# D1H.pdf register map
Vendor: Allwinner; Series: D1H.pdf; File version: 0.1
CPU: XuanTie C906 RISC-V CPU 0, little endian, MPU, FPU, double-precision FPU, 0 interrupt priority bits
Registers are 32-bit, read-write, reset 0x0 unless marked. A register's access mark holds for its fields unless they carry their own. Offsets are from the block's base; [hi:lo] are bit positions; lines under a group give offsets from that group; {n}, {i} and the like mark numbered series; 'fields as' and 'values as' point back to an identical list.

## Audio_Codec (part 1 of 5)
Base 0x02030000
0x00 ANALOG DOMAIN REGISTER group
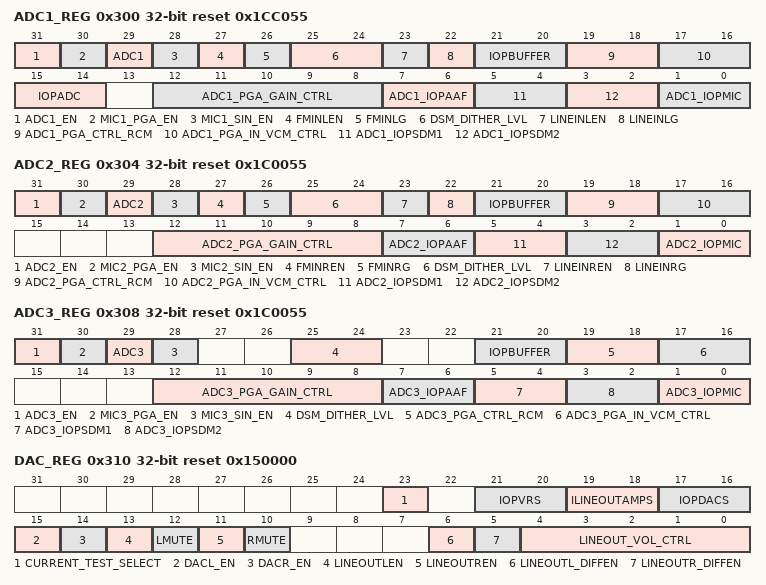
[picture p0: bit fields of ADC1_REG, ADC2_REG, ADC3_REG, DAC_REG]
  0x300 ADC1_REG reset 0x1CC055 — ADC1 Analog Control Register
    [31] ADC1_EN — ADC1 Channel Enable 0: Disabled 1: Enabled
      0=Disabled; 1=Enabled
    [30] MIC1_PGA_EN — MIC1 PGA Enable 0: Disabled 1: Enabled
      0=Disabled; 1=Enabled
    [29] ADC1 — Dither Control 0: New Dither Off 1: New Dither On
      0=New_Dither_Off; 1=New_Dither_On
    [28] MIC1_SIN_EN — MIC1 Single Input Enable 0: Disable 1: Enable
      0=Disable; 1=Enable
    [27] FMINLEN — FMINL Enable 0: Disable 1: Enable
      0=Disable; 1=Enable
    [26] FMINLG — FMINL Gain Control 0: 0 dB 1: 6 dB
      0=_0_dB; 1=_6_dB
    [25:24] DSM_DITHER_LVL — Dither Level Control (Dither level is positive ralated to the ctrl bits) 00: No Level 01: Min Level 10: Middle Level 11: Max Level
      0=No_Level; 1=Min_Level; 2=Middle_Level; 3=Max_Level
    [23] LINEINLEN — LINEINL Enable 0: Disable 1: Enable
      0=Disable; 1=Enable
    [22] LINEINLG — LINEINL Gain Control 0: 0 dB 1: 6 dB
      0=_0_dB; 1=_6_dB
    [21:20] IOPBUFFER — PGA Vcm Buffer OP Bias Current Select 00: 6 uA 01: 7 uA 10: 8 uA 11: 9 uA
      {v}=_{v+6}_uA (v=0..3)
    [19:18] ADC1_PGA_CTRL_RCM — ADC1 PGA Common Mode Input Impedance Control for MICIN 00: 100 kΩ 01: 75 kΩ 10: 50 kΩ 11: 25 kΩ
      0=_100_kΩ; 1=_75_kΩ; 2=_50_kΩ; 3=_25_kΩ
    [17:16] ADC1_PGA_IN_VCM_CTRL — ADC1 PGA Common-Mode Voltage Control 00: 900 mV 01: 800 mV 10: 750 mV 11: 700 mV
      0=_900_mV; 1=_800_mV; 2=_750_mV; 3=_700_mV
    [15:14] IOPADC — ADC1-ADC3 Bias Current Select 00: 1 uA 01: 2 uA 10: 3 uA 11: 4 uA
      {v}=_{v+1}_uA (v=0..3)
    [12:8] ADC1_PGA_GAIN_CTRL — ADC1 PGA gain settings: 0x0: 0 dB 0x10: 21 dB 0x1: 6 dB 0x11: 22 dB 0x2: 6 dB 0x12: 23 dB 0x3: 6 dB 0x13: 24 dB 0x4: 9 dB 0x14: 25 dB 0x5: 10 dB 0x15: 26 dB 0x6: 11 dB 0x16: 27 dB 0x7: 12 dB 0x17: 28 dB 0x8: 13 dB 0x18: 29 dB 0x9: 14 dB 0x19: 30 dB 0xA: 15 dB 0x1A: 31 dB 0xB: 16 dB 0x1B: 32 dB 0xC: 17 dB 0x1C: 33 dB 0xD: 18 dB 0x1D: 34 dB 0xE: 19 dB 0x1E: 35 dB 0xF: 20 dB 0x1F: 36 dB
    [7:6] ADC1_IOPAAF — ADC1 OP AAF Bias Current Select 00: 1.50*IOPADC 01: 1.75*IOPADC 10: 2.00*IOPADC 11: 2.25*IOPADC IOPADC is defined by ADC1_REG<15:14> from 1 uA to 4 uA. For example: ADC1_REG<15:14> = 11, IOPADC = 4 uA 00: 1.50*4 uA = 6 uA 01: 1.75*4 uA = 7 uA 10: 2.00*4 uA = 8 uA 11: 2.25*4 uA = 9 uA
      0=_1_point_50_times_IOPADC (1.50*IOPADC); 1=_1_point_75_times_IOPADC (1.75*IOPADC); 2=_2_point_00_times_IOPADC (2.00*IOPADC); 3=_2_point_25_times_IOPADC (2.25*IOPADC IOPADC is defined by ADC1_REG<15:14> from 1 uA to 4 uA. For example: ADC1_REG<15:14> = 11, IOPADC = 4 uA); 0=_1_point_50_times_4_uA (1.50*4 uA = 6 uA); 1=_1_point_75_times_4_uA (1.75*4 uA = 7 uA); 2=_2_point_00_times_4_uA (2.00*4 uA = 8 uA); 3=_2_point_25_times_4_uA (2.25*4 uA = 9 uA)
    [5:4] ADC1_IOPSDM1 — ADC1 OP SDM Bias Current Select 1 00: 1.50*IOPADC 01: 1.75*IOPADC 10: 2.00*IOPADC 11: 2.25*IOPADC IOPADC is defined by ADC1_REG<15:14> from 1 uA to 4 uA.
      0=_1_point_50_times_IOPADC (1.50*IOPADC); 1=_1_point_75_times_IOPADC (1.75*IOPADC); 2=_2_point_00_times_IOPADC (2.00*IOPADC); 3=_2_point_25_times_IOPADC (2.25*IOPADC IOPADC is defined by ADC1_REG<15:14> from 1 uA to 4 uA.)
    [3:2] ADC1_IOPSDM2 — ADC1 OP SDM Bias Current Select 2 00: 1.50*IOPADC 01: 1.75*IOPADC 10: 2.00*IOPADC 11: 2.25*IOPADC IOPADC is defined by ADC1_REG<15:14> from 1 uA to 4 uA.
      values as ADC1_IOPSDM1
    [1:0] ADC1_IOPMIC — ADC1 OP MIC Bias Current Select 00: 1.50*IOPADC 01: 1.75*IOPADC 10: 2.00*IOPADC 11: 2.25*IOPADC IOPADC is defined by ADC1_REG<15:14> from 1 uA to 4 uA.
      values as ADC1_IOPSDM1
  0x304 ADC2_REG reset 0x1C0055 — ADC2 Analog Control Register
    [31] ADC2_EN — ADC2 Channel Enable 0: Disabled 1: Enabled
      0=Disabled; 1=Enabled
    [30] MIC2_PGA_EN — MIC2 PGA Enable 0: Disabled 1: Enabled
      0=Disabled; 1=Enabled
    [29] ADC2 — Dither Control 0: New Dither Off 1: New Dither On
      0=New_Dither_Off; 1=New_Dither_On
    [28] MIC2_SIN_EN — MIC2 Single Input Enable 0: Disable 1: Enable
      0=Disable; 1=Enable
    [27] FMINREN — FMINR Enable 0: Disable 1: Enable
      0=Disable; 1=Enable
    [26] FMINRG — FMINR Gain Control 0: 0 dB 1: 6 dB
      0=_0_dB; 1=_6_dB
    [25:24] DSM_DITHER_LVL — Dither Level Control (Dither level is positive ralated to the ctrl bits) 00: No Level 01: Min Level 10: Middle Level 11: Max Level
      0=No_Level; 1=Min_Level; 2=Middle_Level; 3=Max_Level
    [23] LINEINREN — LINEINR Enable 0: Disable 1: Enable
      0=Disable; 1=Enable
    [22] LINEINRG — LINEINR Gain Control 0: 0 dB 1: 6 dB
      0=_0_dB; 1=_6_dB
    [21:20] IOPBUFFER — PGA Vcm Buffer OP Bias Current Select 00: 6 uA 01: 7 uA 10: 8 uA 11: 9 uA
      {v}=_{v+6}_uA (v=0..3)
    [19:18] ADC2_PGA_CTRL_RCM — ADC2 PGA Common Mode Input Impedance Control for MICIN 00: 100 kΩ 01: 75 kΩ 10: 50 kΩ 11: 25 kΩ
      0=_100_kΩ; 1=_75_kΩ; 2=_50_kΩ; 3=_25_kΩ
    [17:16] ADC2_PGA_IN_VCM_CTRL — ADC2 PGA Common-Mode Voltage Control 00: 900 mV 01: 800 mV 10: 750 mV 11: 700 mV
      0=_900_mV; 1=_800_mV; 2=_750_mV; 3=_700_mV
    [12:8] ADC2_PGA_GAIN_CTRL — ADC2 PGA Gain Settings 0x0: 0 dB 0x10: 21 dB 0x1: 6 dB 0x11: 22 dB 0x2: 6 dB 0x12: 23 dB 0x3: 6 dB 0x13: 24 dB 0x4: 9 dB 0x14: 25 dB 0x5: 10 dB 0x15: 26 dB 0x6: 11 dB 0x16: 27 dB 0x7: 12 dB 0x17: 28 dB 0x8: 13 dB 0x18: 29 dB 0x9: 14 dB 0x19: 30 dB 0xA: 15 dB 0x1A: 31 dB 0xB: 16 dB 0x1B: 32 dB 0xC: 17 dB 0x1C: 33 dB 0xD: 18 dB 0x1D: 34 dB 0xE: 19 dB 0x1E: 35 dB 0xF: 20 dB 0x1F: 36 dB
    [7:6] ADC2_IOPAAF — ADC2 OP AAF Bias Current Select 00: 1.50*IOPADC 01: 1.75*IOPADC 10: 2.00*IOPADC 11: 2.25*IOPADC IOPADC is defined by ADC1_REG<15:14> from 1 uA to 4 uA.
      values as ANALOG.ADC1_REG.ADC1_IOPSDM1
    [5:4] ADC2_IOPSDM1 — ADC2 OP SDM Bias Current Select 1 00: 1.50*IOPADC 01: 1.75*IOPADC 10: 2.00*IOPADC 11: 2.25*IOPADC IOPADC is defined by ADC1_REG<15:14> from 1 uA to 4 uA.
      values as ANALOG.ADC1_REG.ADC1_IOPSDM1
    [3:2] ADC2_IOPSDM2 — ADC2 OP SDM Bias Current Select 2 00: 1.50*IOPADC 01: 1.75*IOPADC 10: 2.00*IOPADC 11: 2.25*IOPADC IOPADC is defined by ADC1_REG<15:14> from 1 uA to 4 uA.
      values as ANALOG.ADC1_REG.ADC1_IOPSDM1
    [1:0] ADC2_IOPMIC — ADC2 OP MIC Bias Current Select 00: 1.50*IOPADC 01: 1.75*IOPADC 10: 2.00*IOPADC 11: 2.25*IOPADC IOPADC is defined by ADC1_REG<15:14> from 1 uA to 4 uA.
      values as ANALOG.ADC1_REG.ADC1_IOPSDM1
  0x308 ADC3_REG reset 0x1C0055 — ADC3 Analog Control Register
    [31] ADC3_EN — ADC3 Channel Enable 0: Disabled 1: Enabled
      0=Disabled; 1=Enabled
    [30] MIC3_PGA_EN — MIC3 PGA Enable 0: Disabled 1: Enabled
      0=Disabled; 1=Enabled
    [29] ADC3 — Dither Control 0: New Dither Off 1: New Dither On
      0=New_Dither_Off; 1=New_Dither_On
    [28] MIC3_SIN_EN — MIC3 Single Input Enable 0: Disabled 1: Enabled
      0=Disabled; 1=Enabled
    [25:24] DSM_DITHER_LVL — Dither Level Control (Dither level is positive ralated to the ctrl bits) 00: No Level 01: Min Level 10: Middle Level 11: Max Level
      0=No_Level; 1=Min_Level; 2=Middle_Level; 3=Max_Level
    [21:20] IOPBUFFER — PGA Vcm Buffer OP Bias Current Select 00: 6 uA 01: 7 uA 10: 8 uA 11: 9 uA
      {v}=_{v+6}_uA (v=0..3)
    [19:18] ADC3_PGA_CTRL_RCM — ADC3 PGA Common Mode Input Impedance Control for MICIN 00: 100 kΩ 01: 75 kΩ 10: 50 kΩ 11: 25 kΩ
      0=_100_kΩ; 1=_75_kΩ; 2=_50_kΩ; 3=_25_kΩ
    [17:16] ADC3_PGA_IN_VCM_CTRL — ADC3 PGA Common-Mode Voltage Control 00: 900 mV 01: 800 mV 10: 750 mV 11: 700 mV
      0=_900_mV; 1=_800_mV; 2=_750_mV; 3=_700_mV
    [12:8] ADC3_PGA_GAIN_CTRL — ADC3 PGA Gain Settings 0x0: 0 dB 0x10: 21 dB 0x1: 6 dB 0x11: 22 dB 0x2: 6 dB 0x12: 23 dB 0x3: 6 dB 0x13: 24 dB 0x4: 9 dB 0x14: 25 dB 0x5: 10 dB 0x15: 26 dB 0x6: 11 dB 0x16: 27 dB 0x7: 12 dB 0x17: 28 dB 0x8: 13 dB 0x18: 29 dB 0x9: 14 dB 0x19: 30 dB 0xA: 15 dB 0x1A: 31 dB 0xB: 16 dB 0x1B: 32 dB 0xC: 17 dB 0x1C: 33 dB 0xD: 18 dB 0x1D: 34 dB 0xE: 19 dB 0x1E: 35 dB 0xF: 20 dB 0x1F: 36 dB
    [7:6] ADC3_IOPAAF — ADC3 OP AAF Bias Current Select 00: 1.50*IOPADC 01: 1.75*IOPADC 10: 2.00*IOPADC 11: 2.25*IOPADC IOPADC is defined by ADC1_REG<15:14> from 1 uA to 4 uA
      0=_1_point_50_times_IOPADC (1.50*IOPADC); 1=_1_point_75_times_IOPADC (1.75*IOPADC); 2=_2_point_00_times_IOPADC (2.00*IOPADC); 3=_2_point_25_times_IOPADC (2.25*IOPADC IOPADC is defined by ADC1_REG<15:14> from 1 uA to 4 uA)
    [5:4] ADC3_IOPSDM1 — ADC3 OP SDM Bias Current Select 1 00: 1.50*IOPADC 01: 1.75*IOPADC 10: 2.00*IOPADC 11: 2.25*IOPADC IOPADC is defined by ADC1_REG<15:14> from 1 uA to 4 uA
      values as ADC3_IOPAAF
    [3:2] ADC3_IOPSDM2 — ADC3 OP SDM Bias Current Select 2 00: 1.50*IOPADC 01: 1.75*IOPADC 10: 2.00*IOPADC 11: 2.25*IOPADC IOPADC is defined by ADC1_REG<15:14> from 1 uA to 4 uA
      values as ADC3_IOPAAF
    [1:0] ADC3_IOPMIC — ADC3 OP MIC Bias Current Select 00: 1.50*IOPADC 01: 1.75*IOPADC 10: 2.00*IOPADC 11: 2.25*IOPADC IOPADC is defined by ADC1_REG<15:14> from 1 uA to 4 uA
      values as ADC3_IOPAAF
  0x310 DAC_REG reset 0x150000 — DAC Analog Control Register
    [23] CURRENT_TEST_SELECT — Internal Current Sink Test Enable (from MICIN3P pin) 0: Normal 1: For Debug
      0=Normal; 1=For (For Debug)
    [21:20] IOPVRS — VRA2 Buffer OP and Headphone Feedback Buffer OP Bias Current Select 00: 6 uA 01: 7 uA 10: 8 uA 11: 9 uA
      {v}=_{v+6}_uA (v=0..3)
    [19:18] ILINEOUTAMPS — LINEOUTLL/R AMP Bias Current Select 00: 6 uA 01: 7 uA 10: 8 uA 11: 9 uA
      {v}=_{v+6}_uA (v=0..3)
    [17:16] IOPDACS — OPDACL/R Bias Current Select 00: 6 uA 01: 7 uA 10: 8 uA 11: 9 uA
      {v}=_{v+6}_uA (v=0..3)
    [15] DACL_EN — DACL Enable 0: Disabled 1: Enabled
      0=Disabled; 1=Enabled
    [14] DACR_EN — DACR Enable 0: Disabled 1: Enabled
      0=Disabled; 1=Enabled
    [13] LINEOUTLEN — Left Channel LINEOUT Enable 0: Disable 1: Enable
      0=Disable; 1=Enable
    [12] LMUTE — DACL to Left Channel LINEOUT Mute Control 0: Mute 1: Not mute
      0=Mute; 1=Not_mute
    [11] LINEOUTREN — Right Channel LINEOUT Enable 0: Disable 1: Enable
      0=Disable; 1=Enable
    [10] RMUTE — DACR to Right Channel LINEOUT Mute Control 0: Mute 1: Not mute
      0=Mute; 1=Not_mute
    [6] LINEOUTL_DIFFEN — Left Channel LINEOUT Output Control 0: Single-End 1: Differential
      0=single_End; 1=Differential
    [5] LINEOUTR_DIFFEN — Right Channel LINEOUT Output Control 0: Single-End 1: Differential
      0=single_End; 1=Differential
    [4:0] LINEOUT_VOL_CTRL — LINEOUT Volume Control. Total 30 level from 0x1F to 0x02 with the volume 0 dB to -43.5 dB, -1.5 dB/step, mute when 00000 & 00001.
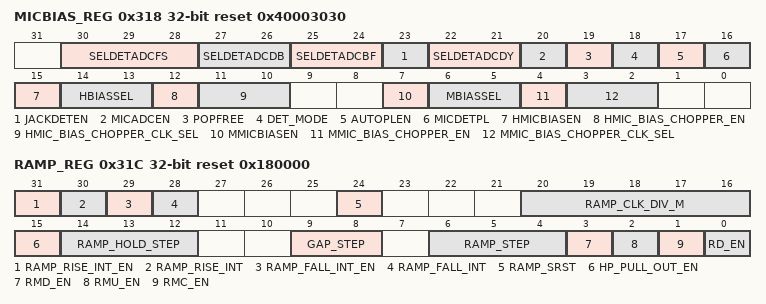
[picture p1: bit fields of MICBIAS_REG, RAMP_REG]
  0x318 MICBIAS_REG reset 0x40003030 — MICBIAS Analog Control Register
    [30:28] SELDETADCFS — Select sample interval of the ADC sample 000: 2 ms … 100: 32 ms … 111: 256 ms
      0=_2_ms; 4=_32_ms; 7=_256_ms
    [27:26] SELDETADCDB — Select debounce time when jack removal 00: 128 ms 01: 256 ms 10: 512 ms 11: 1024 ms
      0=_128_ms; 1=_256_ms; 2=_512_ms; 3=_1024_ms
    [25:24] SELDETADCBF — Select the time to enable HBIAS before MICADC work 00: 2 ms 01: 4 ms 10: 8 ms 11: 16 ms
      0=_2_ms; 1=_4_ms; 2=_8_ms; 3=_16_ms
    [23] JACKDETEN — Jack detect enable 0: Disable 1: Enable
      0=Disable; 1=Enable
    [22:21] SELDETADCDY — Select the delay time to pull low the micdet when jack removal 00: 0.5 ms 01: 1 ms 10: 1.5 ms 11: 2 ms
      0=_0_point_5_ms (0.5 ms); 1=_1_ms; 2=_1_point_5_ms (1.5 ms); 3=_2_ms
    [20] MICADCEN — Microphone detect ADC enable 0: Disabled 1: Enabled
      0=Disabled; 1=Enabled
    [19] POPFREE — When this bit is 0, HBIAS MICADC is controlled by registor
    [18] DET_MODE — MIC Detect Mode 0: Jack in pull low 1: Jack in pull high
      0=Jack_in_pull_low; 1=Jack_in_pull_high
    [17] AUTOPLEN — Enable the function to auto pull low MICDET when jack removal 0: Disabled 1: Enabled
      0=Disabled; 1=Enabled
    [16] MICDETPL — When this bit is 1and AUTOPLEN is 0, the MICDET is pulled down to GND.
    [15] HMICBIASEN — Headphone Microphone Bias Enable 0: Disabled 1: Enabled
      0=Disabled; 1=Enabled
    [14:13] HBIASSEL — HMICBIAS Voltage Level Select 00: 1.88 V 01: 2.09 V 10: 2.33 V 11: 2.55 V
      0=_1_point_88_V (1.88 V); 1=_2_point_09_V (2.09 V); 2=_2_point_33_V (2.33 V); 3=_2_point_55_V (2.55 V)
    [12] HMIC_BIAS_CHOPPER_EN — HMIC BIAS Chopper Enable 0: Disabled 1: Enabled
      0=Disabled; 1=Enabled
    [11:10] HMIC_BIAS_CHOPPER_CLK_SEL — HMIC BIAS Chopper Clock Select 00: 250 kHz 01: 500 kHz 10: 1 MHz 11: 2 MHz
      0=_250_kHz; 1=_500_kHz; 2=1 MHz; 3=2 MHz
    [7] MMICBIASEN — Master Microphone Bias Enable 0: Disabled 1: Enabled
      0=Disabled; 1=Enabled
    [6:5] MBIASSEL — MMICBIAS Voltage Level Select 00: 1.88 V 01: 2.09 V 10: 2.33 V 11: 2.50 V
      0=_1_point_88_V (1.88 V); 1=_2_point_09_V (2.09 V); 2=_2_point_33_V (2.33 V); 3=_2_point_50_V (2.50 V)
    [4] MMIC_BIAS_CHOPPER_EN — MMIC BIAS Chopper Enable 0: Disabled 1: Enabled
      0=Disabled; 1=Enabled
    [3:2] MMIC_BIAS_CHOPPER_CLK_SEL — MMIC BIAS Chopper Clock Select 00: 250 kHz 01: 500 kHz 10: 1 MHz 11: 2 MHz
      0=_250_kHz; 1=_500_kHz; 2=1 MHz; 3=2 MHz
  0x31C RAMP_REG reset 0x180000 — BIAS Analog Control Register
    [31] RAMP_RISE_INT_EN — RAMP Rise Interrupt Enable 0: Enabled 1: Disabled
      0=Enabled; 1=Disabled
    [30] RAMP_RISE_INT write-1-clears — RK Increase Upward Finish and Rampen Pull Down Instruction 0: No Pending IRQ 1: Ramp Rise Finish Pending Interrupt Write ‘1’ to clear this interrupt.
      0=No Pending IRQ; 1=Ramp Rise Finish Pending Interrupt Write ‘1’ to clear this interrupt
    [29] RAMP_FALL_INT_EN — RAMP Fall Int Enable 0: Enabled 1: Disabled
      0=Enabled; 1=Disabled
    [28] RAMP_FALL_INT write-1-clears — RK Downward Decrease Finish and Rampen Pull Down Instruction 0: No Pending IRQ 1: Ramp Fall Finish Pending Interrupt Write ‘1’ to clear this interrupt.
      0=No Pending IRQ; 1=Ramp Fall Finish Pending Interrupt Write ‘1’ to clear this interrupt
    [24] RAMP_SRST — Ramp Soft Reset 0: Disabled 1: Enabled
      0=Disabled; 1=Enabled
    [20:16] RAMP_CLK_DIV_M — Analog Ramp Clk Div Freq Value : M (from 0 to 31, Default: 24). Ana_Ramp_Clk= 24MHz/(M+1) Default Ramp Clk Freq: 24MHz/(24+1)=960 kHz
    [15] HP_PULL_OUT_EN — Heanphone Pullout Enable 0: Disabled 1: Enabled
      0=Disabled; 1=Enabled
    [14:12] RAMP_HOLD_STEP — RAMP HOLD STEP 000: 9600 001: 19200 010: 38400 011: 76800 100: 96000 101: 115200 110: 153600 111: 192000 Ramp Hold Time = Ramp Hold Step/Ramp Clk Freq When Ramp Clk Freq is equal to 960 kHz, the corresponding Ramp Hold time of each gear is: 000: 9600/960 kHz=10 ms 001: 19200/960 kHz=20 ms 010: 38400/960 kHz=40 ms 011: 76800/960 kHz=80 ms 100: 96000/960 kHz=100 ms 101: 115200/960 kHz=120 ms 110: 153600/960 kHz=160 ms 111: 192000/960 kHz=200 ms
      0=_9600; 1=_19200; 2=_38400; 3=_76800; 4=_96000; 5=_115200; 6=_153600; 7=192000 Ramp Hold Time = Ramp Hold Step/Ramp Clk Freq When Ramp Clk Freq is equal to 960 kHz, the corresponding Ramp Hold time of each gear is:; 0=_9600_slash_960_kHz_equals_10 (9600/960 kHz=10 ms); 1=_19200_slash_960_kHz_equals_20 (19200/960 kHz=20 ms); 2=_38400_slash_960_kHz_equals_40 (38400/960 kHz=40 ms); 3=_76800_slash_960_kHz_equals_80 (76800/960 kHz=80 ms); 4=_96000_slash_960_kHz_equals_100 (96000/960 kHz=100 ms); 5=_115200_slash_960_kHz_equals_120 (115200/960 kHz=120 ms); 6=_153600_slash_960_kHz_equals_160 (153600/960 kHz=160 ms); 7=_192000_slash_960_kHz_equals_200 (192000/960 kHz=200 ms)
    [9:8] GAP_STEP — Gap Step 00: ramp step 01: ramp step*2 10: ramp step*3 11: ramp step*4
      0=ramp_step; 1=ramp_step_times_2 (ramp step*2); 2=ramp_step_times_3 (ramp step*3); 3=ramp_step_times_4 (ramp step*4)
    [6:4] RAMP_STEP — RK Frequency Gear, Control Ramp Rise/Fall Total Time 000: 20 001: 30 010: 40 011: 60 100: 80 101: 120 110: 160 111: 240 Ramp Rise/Fall Total Time =(Ramp Step/Ramp Clk Freq)*4096 When Default Ramp Clk Freq is equal to 960 kHz, the corresponding time of each gear is: 000: (20/960kHz)*4096=85.3 ms 001: (30/960kHz)*4096=128 ms 010: (40/960kHz)*4096=170.6 ms 011: (60/960kHz)*4096=256 ms 100: (80/960kHz)*4096=341.3 ms 101: (120/960kHz)*4096=512 ms 110: (160/960kHz)*4096=682.6 ms 111: (240/960kHz)*4096=1024 ms
      0=_20; 1=_30; 2=_40; 3=_60; 4=_80; 5=_120; 6=_160; 7=240 Ramp Rise/Fall Total Time =(Ramp Step/Ramp Clk Freq)*4096 When Default Ramp Clk Freq is equal to 960 kHz, the corresponding time of each gear is:; 0=_openingparen_20_slash_960kHz_closingparen__times_4096_equals_85_point_3_ms ((20/960kHz)*4096=85.3 ms); 1=_openingparen_30_slash_960kHz_closingparen__times_4096_equals_128_ms ((30/960kHz)*4096=128 ms); 2=_openingparen_40_slash_960kHz_closingparen__times_4096_equals_170_point_6_ms ((40/960kHz)*4096=170.6 ms); 3=_openingparen_60_slash_960kHz_closingparen__times_4096_equals_256_ms ((60/960kHz)*4096=256 ms); 4=_openingparen_80_slash_960kHz_closingparen__times_4096_equals_341_point_3_ms ((80/960kHz)*4096=341.3 ms); 5=_openingparen_120_slash_960kHz_closingparen__times_4096_equals_512_ms ((120/960kHz)*4096=512 ms); 6=_openingparen_160_slash_960kHz_closingparen__times_4096_equals_682_point_6_ms ((160/960kHz)*4096=682.6 ms); 7=_openingparen_240_slash_960kHz_closingparen__times_4096_equals_1024_ms ((240/960kHz)*4096=1024 ms)
    [3] RMD_EN — Ramp Manual Down Enable 0: Disabled 1: Enabled
      0=Disabled; 1=Enabled
    [2] RMU_EN — Ramp Manual Up Enable 0: Disabled 1: Enabled
      0=Disabled; 1=Enabled
    [1] RMC_EN — Ramp Manual Control Enable 0: Disabled 1: Enabled
      0=Disabled; 1=Enabled
    [0] RD_EN — Ramp Digital Enable 0: Disabled 1: Enabled
      0=Disabled; 1=Enabled
  0x320 BIAS_REG reset 0x80 — BIAS Analog Control Register
    [7:0] BIASDATA — Bias Current Register Setting Data
